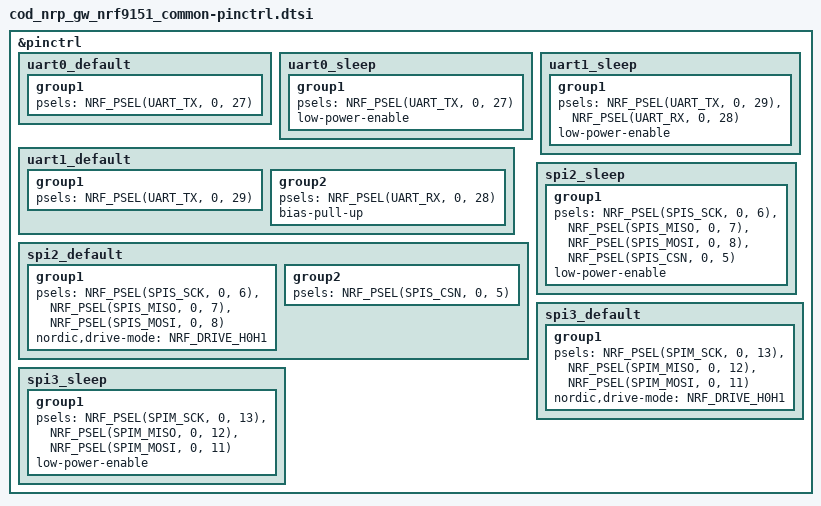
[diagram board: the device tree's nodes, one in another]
/*
* Copyright (c) 2026 Codium Electronique
* SPDX-License-Identifier: Apache-2.0
*/

&pinctrl {
	/*
	 * LOG / console / tracing UART, also used by TF-M.
	 *
	 * WARN: the log uart is TX only,
	 * RX not available, used as busy indicator !
	 */
	uart0_default: uart0_default {
		group1 {
			psels = <NRF_PSEL(UART_TX, 0, 27)>;
		};
	};

	uart0_sleep: uart0_sleep {
		group1 {
			psels = <NRF_PSEL(UART_TX, 0, 27)>;
			low-power-enable;
		};
	};

	/*
	 * 'OTA' UART, can be used by mcumgr SMP or shell
	 */
	uart1_default: uart1_default {
		group1 {
			psels = <NRF_PSEL(UART_TX, 0, 29)>;
		};

		group2 {
			psels = <NRF_PSEL(UART_RX, 0, 28)>;
			bias-pull-up;
		};
	};

	uart1_sleep: uart1_sleep {
		group1 {
			psels = <NRF_PSEL(UART_TX, 0, 29)>,
				<NRF_PSEL(UART_RX, 0, 28)>;
			low-power-enable;
		};
	};

	/* SPI wired to Linux SoM */
	spi2_default: spi2_default {
		group1 {
			psels = <NRF_PSEL(SPIS_SCK, 0, 6)>,
				<NRF_PSEL(SPIS_MISO, 0, 7)>,
				<NRF_PSEL(SPIS_MOSI, 0, 8)>;
			nordic,drive-mode = <NRF_DRIVE_H0H1>;
		};

		group2 {
			psels = <NRF_PSEL(SPIS_CSN, 0, 5)>;
		};
	};

	spi2_sleep: spi2_sleep {
		group1 {
			psels = <NRF_PSEL(SPIS_SCK, 0, 6)>,
				<NRF_PSEL(SPIS_MISO, 0, 7)>,
				<NRF_PSEL(SPIS_MOSI, 0, 8)>,
				<NRF_PSEL(SPIS_CSN, 0, 5)>;
			low-power-enable;
		};
	};

	/* MX25R1635F 16Mbits external flash */
	spi3_default: spi3_default {
		group1 {
			psels = <NRF_PSEL(SPIM_SCK, 0, 13)>,
				<NRF_PSEL(SPIM_MISO, 0, 12)>,
				<NRF_PSEL(SPIM_MOSI, 0, 11)>;
			nordic,drive-mode = <NRF_DRIVE_H0H1>;
		};
	};

	spi3_sleep: spi3_sleep {
		group1 {
			psels = <NRF_PSEL(SPIM_SCK, 0, 13)>,
				<NRF_PSEL(SPIM_MISO, 0, 12)>,
				<NRF_PSEL(SPIM_MOSI, 0, 11)>;
			low-power-enable;
		};
	};
};
